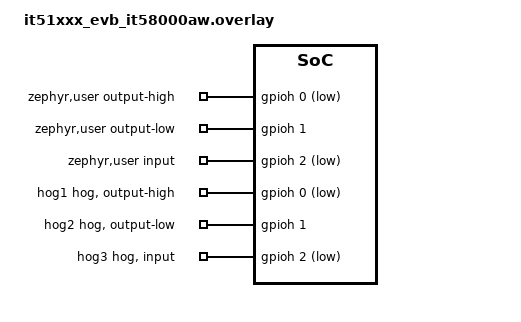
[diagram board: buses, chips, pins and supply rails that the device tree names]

#include <zephyr/dt-bindings/gpio/gpio.h>

/ {
	zephyr,user {
		output-high-gpios = <&gpioh 0 GPIO_ACTIVE_LOW>;
		output-low-gpios = <&gpioh 1 GPIO_ACTIVE_HIGH>;
		input-gpios = <&gpioh 2 GPIO_ACTIVE_LOW>;
	};
};

&gpioh {
	hog1 {
		gpio-hog;
		gpios = <0 GPIO_ACTIVE_LOW>;
		output-high;
	};

	hog2 {
		gpio-hog;
		gpios = <1 GPIO_ACTIVE_HIGH>;
		output-low;
	};

	hog3 {
		gpio-hog;
		gpios = <2 GPIO_ACTIVE_LOW>;
		input;
	};
};
